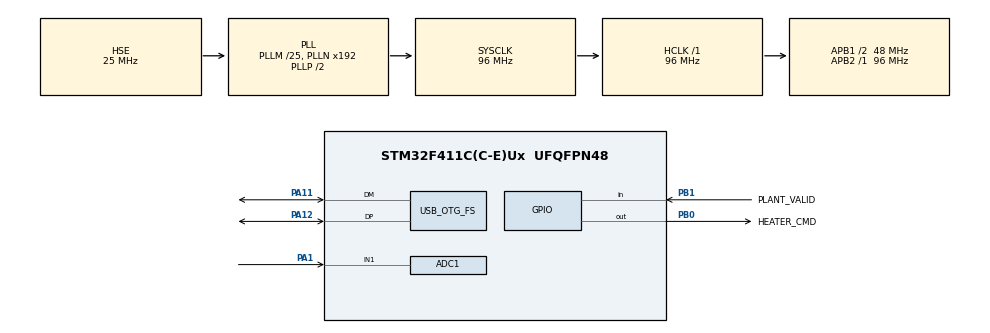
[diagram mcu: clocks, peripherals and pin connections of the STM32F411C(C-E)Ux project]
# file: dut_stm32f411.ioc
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ADC1.Channel-0\#ChannelRegularConversion=ADC_CHANNEL_1
ADC1.NbrOfConversion=1
ADC1.NbrOfConversionFlag=1
ADC1.Rank-0\#ChannelRegularConversion=1
ADC1.SamplingTime-0\#ChannelRegularConversion=ADC_SAMPLETIME_144CYCLES
ADC1.master=1
Mcu.Family=STM32F4
Mcu.Name=STM32F411C(C-E)Ux
Mcu.Package=UFQFPN48
NVIC.OTG_FS_IRQn=true\:0\:0\:false\:false\:true\:false\:true\:true
NVIC.PriorityGroup=NVIC_PRIORITYGROUP_4
NVIC.TIM2_IRQn=true\:0\:0\:false\:false\:true\:true\:true\:true
PA1.Signal=ADCx_IN1
PA11.Mode=Device_Only
PA11.Signal=USB_OTG_FS_DM
PA12.Mode=Device_Only
PA12.Signal=USB_OTG_FS_DP
PA13.Mode=Serial_Wire
PA13.Signal=SYS_JTMS-SWDIO
PA14.Mode=Serial_Wire
PA14.Signal=SYS_JTCK-SWCLK
PB0.GPIO_Label=HEATER_CMD
PB0.Signal=GPIO_Output
PB1.GPIO_Label=PLANT_VALID
PB1.Signal=GPIO_Input
PH0\ -\ OSC_IN.Mode=HSE-External-Oscillator
PH0\ -\ OSC_IN.Signal=RCC_OSC_IN
PH1\ -\ OSC_OUT.Mode=HSE-External-Oscillator
PH1\ -\ OSC_OUT.Signal=RCC_OSC_OUT
ProjectManager.HeapSize=0x200
ProjectManager.StackSize=0x400
ProjectManager.TargetToolchain=CMake
RCC.48MHZClocksFreq_Value=48000000
RCC.AHBFreq_Value=96000000
RCC.APB1CLKDivider=RCC_HCLK_DIV2
RCC.APB1Freq_Value=48000000
RCC.APB1TimFreq_Value=96000000
RCC.APB2Freq_Value=96000000
RCC.APB2TimFreq_Value=96000000
RCC.CortexFreq_Value=96000000
RCC.HCLKFreq_Value=96000000
RCC.HSE_VALUE=25000000
RCC.HSI_VALUE=16000000
RCC.LSE_VALUE=32768
RCC.PLLM=25
RCC.SYSCLKFreq_VALUE=96000000
RCC.SYSCLKSource=RCC_SYSCLKSOURCE_PLLCLK
RCC.VCOOutputFreq_Value=192000000
SH.ADCx_IN1.0=ADC1_IN1,IN1
TIM2.Period=9999
TIM2.Prescaler=9599
USB_DEVICE.CLASS_NAME_FS=CDC
USB_DEVICE.VirtualMode=Cdc
USB_DEVICE.VirtualModeFS=Cdc_FS
USB_OTG_FS.Sof_enable=DISABLE
USB_OTG_FS.VirtualMode=Device_Only
USB_OTG_FS.low_power_enable=DISABLE
USB_OTG_FS.lpm_enable=DISABLE
VP_TIM2_VS_ClockSourceINT.Mode=Internal
VP_USB_DEVICE_VS_USB_DEVICE_CDC_FS.Mode=CDC_FS
board=custom

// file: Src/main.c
/* USER CODE BEGIN Header */
/**
  ******************************************************************************
  * @file           : main.c
  * @brief          : Main program body
  ******************************************************************************
  * @attention
  *
  * Copyright (c) 2026 STMicroelectronics.
  * All rights reserved.
  *
  * This software is licensed under terms that can be found in the LICENSE file
  * in the root directory of this software component.
  * If no LICENSE file comes with this software, it is provided AS-IS.
  *
  ******************************************************************************
  */
/* USER CODE END Header */
#include "main.h"
#include "usb_device.h"

/* USER CODE BEGIN Includes */
#include "hil_board_transport.h"
#include "dut_app.h"
#include "dut_runtime.h"

/* USER CODE END Includes */

ADC_HandleTypeDef hadc1;

TIM_HandleTypeDef htim2;

void SystemClock_Config(void);
static void MX_GPIO_Init(void);
static void MX_ADC1_Init(void);
static void MX_TIM2_Init(void);

int main(void)
{

  /* MCU Configuration--------------------------------------------------------*/

  /* Reset of all peripherals, Initializes the Flash interface and the Systick. */
  HAL_Init();

  /* Configure the system clock */
  SystemClock_Config();

  /* Initialize all configured peripherals */
  MX_GPIO_Init();
  MX_ADC1_Init();
  MX_USB_DEVICE_Init();
  MX_TIM2_Init();
  /* USER CODE BEGIN 2 */
  dut_transport_init();
  dut_app_init();

  /* USER CODE END 2 */

  /* Infinite loop */
  /* USER CODE BEGIN WHILE */
  while (1)
  {
    dut_transport_service();
    dut_app_service();
    /* USER CODE END WHILE */

  }
}

void SystemClock_Config(void)
{
  RCC_OscInitTypeDef RCC_OscInitStruct = {0};
  RCC_ClkInitTypeDef RCC_ClkInitStruct = {0};

  /** Configure the main internal regulator output voltage
  */
  __HAL_RCC_PWR_CLK_ENABLE();
  __HAL_PWR_VOLTAGESCALING_CONFIG(PWR_REGULATOR_VOLTAGE_SCALE1);

  /** Initializes the RCC Oscillators according to the specified parameters
  * in the RCC_OscInitTypeDef structure.
  */
  RCC_OscInitStruct.OscillatorType = RCC_OSCILLATORTYPE_HSE;
  RCC_OscInitStruct.HSEState = RCC_HSE_ON;
  RCC_OscInitStruct.PLL.PLLState = RCC_PLL_ON;
  RCC_OscInitStruct.PLL.PLLSource = RCC_PLLSOURCE_HSE;
  RCC_OscInitStruct.PLL.PLLM = 25;
  RCC_OscInitStruct.PLL.PLLN = 192;
  RCC_OscInitStruct.PLL.PLLP = RCC_PLLP_DIV2;
  RCC_OscInitStruct.PLL.PLLQ = 4;
  if (HAL_RCC_OscConfig(&RCC_OscInitStruct) != HAL_OK)
  {
    Error_Handler();
  }

  /** Initializes the CPU, AHB and APB buses clocks
  */
  RCC_ClkInitStruct.ClockType = RCC_CLOCKTYPE_HCLK|RCC_CLOCKTYPE_SYSCLK
                              |RCC_CLOCKTYPE_PCLK1|RCC_CLOCKTYPE_PCLK2;
  RCC_ClkInitStruct.SYSCLKSource = RCC_SYSCLKSOURCE_PLLCLK;
  RCC_ClkInitStruct.AHBCLKDivider = RCC_SYSCLK_DIV1;
  RCC_ClkInitStruct.APB1CLKDivider = RCC_HCLK_DIV2;
  RCC_ClkInitStruct.APB2CLKDivider = RCC_HCLK_DIV1;

  if (HAL_RCC_ClockConfig(&RCC_ClkInitStruct, FLASH_LATENCY_3) != HAL_OK)
  {
    Error_Handler();
  }
}

static void MX_ADC1_Init(void)
{

  ADC_ChannelConfTypeDef sConfig = {0};

  /** Configure the global features of the ADC (Clock, Resolution, Data Alignment and number of conversion)
  */
  hadc1.Instance = ADC1;
  hadc1.Init.ClockPrescaler = ADC_CLOCK_SYNC_PCLK_DIV4;
  hadc1.Init.Resolution = ADC_RESOLUTION_12B;
  hadc1.Init.ScanConvMode = DISABLE;
  hadc1.Init.ContinuousConvMode = DISABLE;
  hadc1.Init.DiscontinuousConvMode = DISABLE;
  hadc1.Init.ExternalTrigConvEdge = ADC_EXTERNALTRIGCONVEDGE_NONE;
  hadc1.Init.ExternalTrigConv = ADC_SOFTWARE_START;
  hadc1.Init.DataAlign = ADC_DATAALIGN_RIGHT;
  hadc1.Init.NbrOfConversion = 1;
  hadc1.Init.DMAContinuousRequests = DISABLE;
  hadc1.Init.EOCSelection = ADC_EOC_SINGLE_CONV;
  if (HAL_ADC_Init(&hadc1) != HAL_OK)
  {
    Error_Handler();
  }

  /** Configure for the selected ADC regular channel its corresponding rank in the sequencer and its sample time.
  */
  sConfig.Channel = ADC_CHANNEL_1;
  sConfig.Rank = 1;
  sConfig.SamplingTime = ADC_SAMPLETIME_144CYCLES;
  if (HAL_ADC_ConfigChannel(&hadc1, &sConfig) != HAL_OK)
  {
    Error_Handler();
  }

}

static void MX_TIM2_Init(void)
{

  TIM_ClockConfigTypeDef sClockSourceConfig = {0};
  TIM_MasterConfigTypeDef sMasterConfig = {0};

  htim2.Instance = TIM2;
  htim2.Init.Prescaler = 9599;
  htim2.Init.CounterMode = TIM_COUNTERMODE_UP;
  htim2.Init.Period = 9999;
  htim2.Init.ClockDivision = TIM_CLOCKDIVISION_DIV1;
  htim2.Init.AutoReloadPreload = TIM_AUTORELOAD_PRELOAD_DISABLE;
  if (HAL_TIM_Base_Init(&htim2) != HAL_OK)
  {
    Error_Handler();
  }
  sClockSourceConfig.ClockSource = TIM_CLOCKSOURCE_INTERNAL;
  if (HAL_TIM_ConfigClockSource(&htim2, &sClockSourceConfig) != HAL_OK)
  {
    Error_Handler();
  }
  sMasterConfig.MasterOutputTrigger = TIM_TRGO_RESET;
  sMasterConfig.MasterSlaveMode = TIM_MASTERSLAVEMODE_DISABLE;
  if (HAL_TIMEx_MasterConfigSynchronization(&htim2, &sMasterConfig) != HAL_OK)
  {
    Error_Handler();
  }

}

static void MX_GPIO_Init(void)
{
  GPIO_InitTypeDef GPIO_InitStruct = {0};

  /* GPIO Ports Clock Enable */
  __HAL_RCC_GPIOH_CLK_ENABLE();
  __HAL_RCC_GPIOA_CLK_ENABLE();
  __HAL_RCC_GPIOB_CLK_ENABLE();

  /*Configure GPIO pin Output Level */
  HAL_GPIO_WritePin(HEATER_CMD_GPIO_Port, HEATER_CMD_Pin, GPIO_PIN_RESET);

  /*Configure GPIO pin : HEATER_CMD_Pin */
  GPIO_InitStruct.Pin = HEATER_CMD_Pin;
  GPIO_InitStruct.Mode = GPIO_MODE_OUTPUT_PP;
  GPIO_InitStruct.Pull = GPIO_NOPULL;
  GPIO_InitStruct.Speed = GPIO_SPEED_FREQ_LOW;
  HAL_GPIO_Init(HEATER_CMD_GPIO_Port, &GPIO_InitStruct);

  /*Configure GPIO pin : PLANT_VALID_Pin */
  GPIO_InitStruct.Pin = PLANT_VALID_Pin;
  GPIO_InitStruct.Mode = GPIO_MODE_INPUT;
  GPIO_InitStruct.Pull = GPIO_NOPULL;
  HAL_GPIO_Init(PLANT_VALID_GPIO_Port, &GPIO_InitStruct);

}

void Error_Handler(void)
{
  /* USER CODE BEGIN Error_Handler_Debug */
  dut_force_safe_output();
  /* User can add his own implementation to report the HAL error return state */
  __disable_irq();
  while (1)
  {
  }
  /* USER CODE END Error_Handler_Debug */
}
